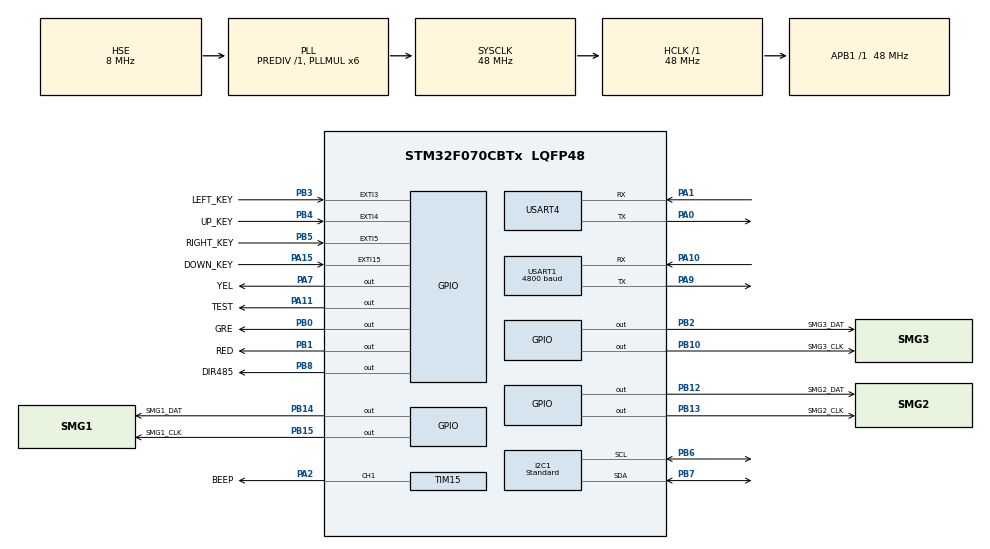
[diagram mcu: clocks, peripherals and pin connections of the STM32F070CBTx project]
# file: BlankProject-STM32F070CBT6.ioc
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I2C1.I2C_Speed_Mode=I2C_Standard
I2C1.Timing=0x00201D2B
Mcu.Family=STM32F0
Mcu.Name=STM32F070CBTx
Mcu.Package=LQFP48
NVIC.EXTI2_3_IRQn=true\:0\:0\:false\:false\:true\:true\:true\:true
NVIC.EXTI4_15_IRQn=true\:0\:0\:false\:false\:true\:true\:true\:true
NVIC.TIM6_IRQn=true\:0\:0\:false\:false\:true\:true\:true\:true
NVIC.USART1_IRQn=true\:0\:0\:false\:false\:true\:true\:true\:true
NVIC.USART3_4_IRQn=true\:0\:0\:false\:false\:true\:true\:true\:true
PA0.Mode=Asynchronous
PA0.Signal=USART4_TX
PA1.Mode=Asynchronous
PA1.Signal=USART4_RX
PA10.Mode=Asynchronous
PA10.Signal=USART1_RX
PA11.GPIO_Label=TEST
PA11.GPIO_Speed=GPIO_SPEED_FREQ_HIGH
PA11.PinState=GPIO_PIN_SET
PA11.Signal=GPIO_Output
PA13.Mode=Serial_Wire
PA13.Signal=SYS_SWDIO
PA14.Mode=Serial_Wire
PA14.Signal=SYS_SWCLK
PA15.GPIO_Label=DOWN_KEY
PA15.Signal=GPXTI15
PA2.GPIO_Label=BEEP
PA2.Signal=S_TIM15_CH1
PA7.GPIO_Label=YEL
PA7.Signal=GPIO_Output
PA9.Mode=Asynchronous
PA9.Signal=USART1_TX
PB0.GPIO_Label=GRE
PB0.Signal=GPIO_Output
PB1.GPIO_Label=RED
PB1.Signal=GPIO_Output
PB10.GPIO_Label=SMG3_CLK
PB10.GPIO_ModeDefaultOutputPP=GPIO_MODE_OUTPUT_OD
PB10.GPIO_PuPd=GPIO_NOPULL
PB10.GPIO_Speed=GPIO_SPEED_FREQ_HIGH
PB10.PinState=GPIO_PIN_SET
PB10.Signal=GPIO_Output
PB12.GPIO_Label=SMG2_DAT
PB12.GPIO_ModeDefaultOutputPP=GPIO_MODE_OUTPUT_OD
PB12.GPIO_PuPd=GPIO_NOPULL
PB12.GPIO_Speed=GPIO_SPEED_FREQ_HIGH
PB12.PinState=GPIO_PIN_SET
PB12.Signal=GPIO_Output
PB13.GPIO_Label=SMG2_CLK
PB13.GPIO_ModeDefaultOutputPP=GPIO_MODE_OUTPUT_OD
PB13.GPIO_PuPd=GPIO_NOPULL
PB13.GPIO_Speed=GPIO_SPEED_FREQ_HIGH
PB13.PinState=GPIO_PIN_SET
PB13.Signal=GPIO_Output
PB14.GPIO_Label=SMG1_DAT
PB14.GPIO_ModeDefaultOutputPP=GPIO_MODE_OUTPUT_OD
PB14.GPIO_PuPd=GPIO_NOPULL
PB14.GPIO_Speed=GPIO_SPEED_FREQ_HIGH
PB14.PinState=GPIO_PIN_SET
PB14.Signal=GPIO_Output
PB15.GPIO_Label=SMG1_CLK
PB15.GPIO_ModeDefaultOutputPP=GPIO_MODE_OUTPUT_OD
PB15.GPIO_PuPd=GPIO_NOPULL
PB15.GPIO_Speed=GPIO_SPEED_FREQ_HIGH
PB15.PinState=GPIO_PIN_SET
PB15.Signal=GPIO_Output
PB2.GPIO_Label=SMG3_DAT
PB2.GPIO_ModeDefaultOutputPP=GPIO_MODE_OUTPUT_OD
PB2.GPIO_PuPd=GPIO_NOPULL
PB2.GPIO_Speed=GPIO_SPEED_FREQ_HIGH
PB2.PinState=GPIO_PIN_SET
PB2.Signal=GPIO_Output
PB3.GPIO_Label=LEFT_KEY
PB3.Signal=GPXTI3
PB4.GPIO_Label=UP_KEY
PB4.Signal=GPXTI4
PB5.GPIO_Label=RIGHT_KEY
PB5.Signal=GPXTI5
PB6.Mode=I2C
PB6.Signal=I2C1_SCL
PB7.Mode=I2C
PB7.Signal=I2C1_SDA
PB8.GPIO_Label=DIR485
PB8.Signal=GPIO_Output
PF0-OSC_IN.Mode=HSE-External-Oscillator
PF0-OSC_IN.Signal=RCC_OSC_IN
PF1-OSC_OUT.Mode=HSE-External-Oscillator
PF1-OSC_OUT.Signal=RCC_OSC_OUT
ProjectManager.HeapSize=0x200
ProjectManager.StackSize=0x400
ProjectManager.TargetToolchain=CMake
RCC.AHBFreq_Value=48000000
RCC.APB1Freq_Value=48000000
RCC.APB1TimFreq_Value=48000000
RCC.HCLKFreq_Value=48000000
RCC.PLLMUL=RCC_PLL_MUL6
RCC.PLLSourceVirtual=RCC_PLLSOURCE_HSE
RCC.SYSCLKFreq_VALUE=48000000
RCC.SYSCLKSource=RCC_SYSCLKSOURCE_PLLCLK
SH.S_TIM15_CH1.0=TIM15_CH1,PWM Generation1 CH1
TIM15.AutoReloadPreload=TIM_AUTORELOAD_PRELOAD_ENABLE
TIM15.Channel-PWM\ Generation1\ CH1=TIM_CHANNEL_1
TIM15.Period=249
TIM15.Prescaler=47
TIM6.Period=499
TIM6.Prescaler=47999
USART1.BaudRate=4800
USART1.Parity=PARITY_ODD
USART1.VirtualMode-Asynchronous=VM_ASYNC
USART1.WordLength=WORDLENGTH_9B
USART4.VirtualMode-Asynchronous=VM_ASYNC
VP_TIM15_VS_ClockSourceINT.Mode=Internal
VP_TIM6_VS_ClockSourceINT.Mode=Enable_Timer
board=custom

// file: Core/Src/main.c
/* USER CODE BEGIN Header */
/* USER CODE END Header */
#include "main.h"
#include "i2c.h"
#include "tim.h"
#include "usart.h"
#include "gpio.h"

/* USER CODE BEGIN Includes */
#include "led.h"
#include "buzzer.h"
#include "ledsegdisp.h"
/* USER CODE END Includes */

void SystemClock_Config(void);

int main(void) {

    /* MCU Configuration--------------------------------------------------------*/

    /* Reset of all peripherals, Initializes the Flash interface and the Systick. */
    HAL_Init();

    /* Configure the system clock */
    SystemClock_Config();

    /* Initialize all configured peripherals */
    MX_GPIO_Init();
    MX_I2C1_Init();
    MX_USART1_UART_Init();
    MX_USART4_UART_Init();
    MX_TIM15_Init();
    MX_TIM6_Init();

    /* Infinite loop */
    while (1) {

    }
}

void SystemClock_Config(void) {
    RCC_OscInitTypeDef RCC_OscInitStruct = {0};
    RCC_ClkInitTypeDef RCC_ClkInitStruct = {0};
    RCC_PeriphCLKInitTypeDef PeriphClkInit = {0};

    /** Initializes the RCC Oscillators according to the specified parameters
    * in the RCC_OscInitTypeDef structure.
    */
    RCC_OscInitStruct.OscillatorType = RCC_OSCILLATORTYPE_HSI | RCC_OSCILLATORTYPE_HSE;
    RCC_OscInitStruct.HSEState = RCC_HSE_ON;
    RCC_OscInitStruct.HSIState = RCC_HSI_ON;
    RCC_OscInitStruct.HSICalibrationValue = RCC_HSICALIBRATION_DEFAULT;
    RCC_OscInitStruct.PLL.PLLState = RCC_PLL_ON;
    RCC_OscInitStruct.PLL.PLLSource = RCC_PLLSOURCE_HSE;
    RCC_OscInitStruct.PLL.PLLMUL = RCC_PLL_MUL6;
    RCC_OscInitStruct.PLL.PREDIV = RCC_PREDIV_DIV1;
    if (HAL_RCC_OscConfig(&RCC_OscInitStruct) != HAL_OK) {
        Error_Handler();
    }

    /** Initializes the CPU, AHB and APB buses clocks
    */
    RCC_ClkInitStruct.ClockType = RCC_CLOCKTYPE_HCLK | RCC_CLOCKTYPE_SYSCLK
                                  | RCC_CLOCKTYPE_PCLK1;
    RCC_ClkInitStruct.SYSCLKSource = RCC_SYSCLKSOURCE_PLLCLK;
    RCC_ClkInitStruct.AHBCLKDivider = RCC_SYSCLK_DIV1;
    RCC_ClkInitStruct.APB1CLKDivider = RCC_HCLK_DIV1;

    if (HAL_RCC_ClockConfig(&RCC_ClkInitStruct, FLASH_LATENCY_1) != HAL_OK) {
        Error_Handler();
    }
    PeriphClkInit.PeriphClockSelection = RCC_PERIPHCLK_USART1 | RCC_PERIPHCLK_I2C1;
    PeriphClkInit.Usart1ClockSelection = RCC_USART1CLKSOURCE_PCLK1;
    PeriphClkInit.I2c1ClockSelection = RCC_I2C1CLKSOURCE_HSI;
    if (HAL_RCCEx_PeriphCLKConfig(&PeriphClkInit) != HAL_OK) {
        Error_Handler();
    }
}

void Error_Handler(void) {
}
